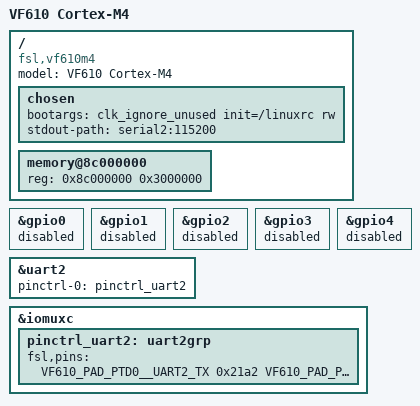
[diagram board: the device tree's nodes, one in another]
// SPDX-License-Identifier: GPL-2.0+ OR MIT
/*
 * Device tree for Colibri VF61 Cortex-M4 support
 *
 * Copyright (C) 2015 Stefan Agner
 */

/dts-v1/;
#include "vf610m4.dtsi"

/ {
	model = "VF610 Cortex-M4";
	compatible = "fsl,vf610m4";

	chosen {
		bootargs = "clk_ignore_unused init=/linuxrc rw";
		stdout-path = "serial2:115200";
	};

	memory@8c000000 {
		device_type = "memory";
		reg = <0x8c000000 0x3000000>;
	};
};

&gpio0 {
	status = "disabled";
};

&gpio1 {
	status = "disabled";
};

&gpio2 {
	status = "disabled";
};

&gpio3 {
	status = "disabled";
};

&gpio4 {
	status = "disabled";
};

&uart2 {
	pinctrl-names = "default";
	pinctrl-0 = <&pinctrl_uart2>;
	status = "okay";
};

&iomuxc {
	pinctrl_uart2: uart2grp {
		fsl,pins = <
			VF610_PAD_PTD0__UART2_TX		0x21a2
			VF610_PAD_PTD1__UART2_RX		0x21a1
			VF610_PAD_PTD2__UART2_RTS		0x21a2
			VF610_PAD_PTD3__UART2_CTS		0x21a1
		>;
	};
};
